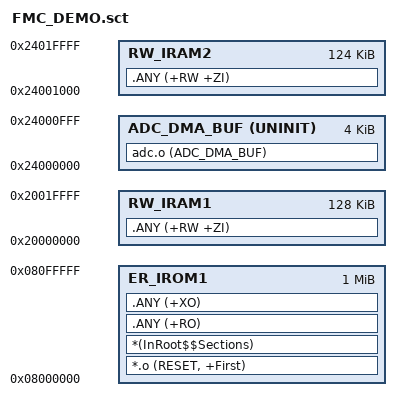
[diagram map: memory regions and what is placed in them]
; *************************************************************
; *** Scatter-Loading Description File generated by uVision ***
; *************************************************************

LR_IROM1 0x08000000 0x00100000  {    ; load region size_region
  ER_IROM1 0x08000000 0x00100000  {  ; load address = execution address
   *.o (RESET, +First)
   *(InRoot$$Sections)
   .ANY (+RO)
   .ANY (+XO)
  }
  RW_IRAM1 0x20000000 0x00020000  {  ; DTCM 128 KB
   .ANY (+RW +ZI)
  }
  ; ADC_DMA_BUF: ping-pong buffer in AXI SRAM (512 halfwords x 2 = 2 KB)
  ; UNINIT keeps startup code from zeroing it (DMA fills it before CPU reads)
  ADC_DMA_BUF 0x24000000 UNINIT 0x00001000 {
   adc.o (ADC_DMA_BUF)
  }
  RW_IRAM2 0x24001000 0x0001F000  {  ; AXI SRAM remaining ~124 KB
   .ANY (+RW +ZI)
  }
}
